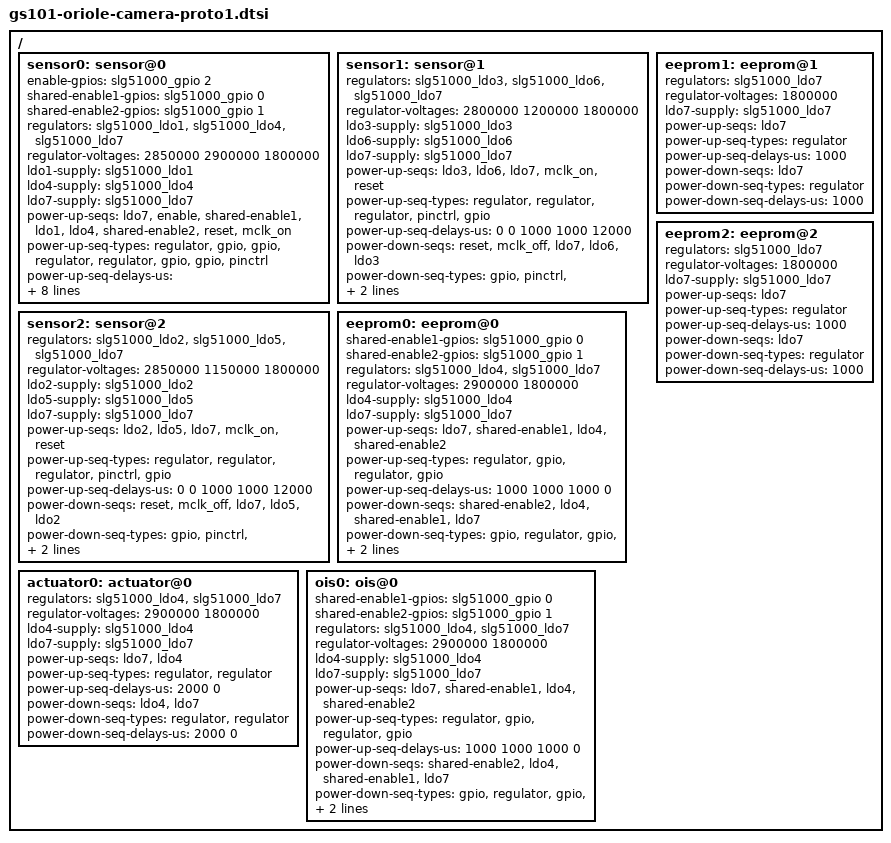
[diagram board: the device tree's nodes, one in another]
// SPDX-License-Identifier: GPL-2.0-only
/*
 * gs101 camera lwis device tree source for oriole
 *
 * Copyright 2020 Google LLC.
 *
 */

/ {
	fragment@lwiscamera {
		target-path = "/";
		__overlay__ {
			/* REAR CAMERA GN1 */
			sensor0: sensor@0 {
				enable-gpios =
					<&slg51000_gpio 2 GPIO_ACTIVE_HIGH>;

				/* GPIOs */
				shared-enable1-gpios =
					<&slg51000_gpio 0 GPIO_ACTIVE_HIGH>;
				shared-enable2-gpios =
					<&slg51000_gpio 1 GPIO_ACTIVE_HIGH>;

				/* Power supplies */
				regulators =
					<&slg51000_ldo1 &slg51000_ldo4
					 &slg51000_ldo7>;
				regulator-voltages =
					<2850000 2900000
					 1800000>;
				ldo1-supply = <&slg51000_ldo1>;
				ldo4-supply = <&slg51000_ldo4>;
				ldo7-supply = <&slg51000_ldo7>;

				/* Power up sequence */
				power-up-seqs =
					"ldo7",
					"enable",
					"shared-enable1",
					"ldo1",
					"ldo4",
					"shared-enable2",
					"reset",
					"mclk_on";
				power-up-seq-types =
					"regulator",
					"gpio",
					"gpio",
					"regulator",
					"regulator",
					"gpio",
					"gpio",
					"pinctrl";
				power-up-seq-delays-us =
					<1000
					 0
					 1000
					 0
					 1000
					 0
					 1000
					 9000>;

				/* Power down sequence */
				power-down-seqs =
					"mclk_off",
					"reset",
					"shared-enable2",
					"ldo4",
					"ldo1",
					"shared-enable1",
					"enable",
					"ldo7";
				power-down-seq-types =
					"pinctrl",
					"gpio",
					"gpio",
					"regulator",
					"regulator",
					"gpio",
					"gpio",
					"regulator";
				power-down-seq-delays-us =
					<1000
					 0
					 1000
					 0
					 1000
					 0
					 1000
					 0>;
			};

			/* FRONT CAMERA IMX355 */
			sensor1: sensor@1 {
				/* Power supplies */
				regulators =
					<&slg51000_ldo3 &slg51000_ldo6
					 &slg51000_ldo7>;
				regulator-voltages =
					<2800000 1200000
					 1800000>;
				ldo3-supply = <&slg51000_ldo3>;
				ldo6-supply = <&slg51000_ldo6>;
				ldo7-supply = <&slg51000_ldo7>;

				/* Power up sequence */
				power-up-seqs =
					"ldo3",
					"ldo6",
					"ldo7",
					"mclk_on",
					"reset";
				power-up-seq-types =
					"regulator",
					"regulator",
					"regulator",
					"pinctrl",
					"gpio";
				power-up-seq-delays-us =
					<0
					 0
					 1000
					 1000
					 12000>;

				/* Power down sequence */
				power-down-seqs =
					"reset",
					"mclk_off",
					"ldo7",
					"ldo6",
					"ldo3";
				power-down-seq-types =
					"gpio",
					"pinctrl",
					"regulator",
					"regulator",
					"regulator";
				power-down-seq-delays-us =
					<0
					 1000
					 0
					 0
					 0>;
			};

			/* REAR ULTRA WIDE CAMERA IMX386 */
			sensor2: sensor@2 {
				/* Power supplies */
				regulators =
					<&slg51000_ldo2 &slg51000_ldo5
					 &slg51000_ldo7>;
				regulator-voltages =
					<2850000 1150000
					 1800000>;
				ldo2-supply = <&slg51000_ldo2>;
				ldo5-supply = <&slg51000_ldo5>;
				ldo7-supply = <&slg51000_ldo7>;

				/* Power up sequence */
				power-up-seqs =
					"ldo2",
					"ldo5",
					"ldo7",
					"mclk_on",
					"reset";
				power-up-seq-types =
					"regulator",
					"regulator",
					"regulator",
					"pinctrl",
					"gpio";
				power-up-seq-delays-us =
					<0
					 0
					 1000
					 1000
					 12000>;

				/* Power down sequence */
				power-down-seqs =
					"reset",
					"mclk_off",
					"ldo7",
					"ldo5",
					"ldo2";
				power-down-seq-types =
					"gpio",
					"pinctrl",
					"regulator",
					"regulator",
					"regulator";
				power-down-seq-delays-us =
					<0
					 1000
					 0
					 0
					 0>;
			};

			/* Eeprom lc898128 for gn1*/
			eeprom0: eeprom@0 {
				/* GPIOs */
				shared-enable1-gpios =
					<&slg51000_gpio 0 GPIO_ACTIVE_HIGH>;
				shared-enable2-gpios =
					<&slg51000_gpio 1 GPIO_ACTIVE_HIGH>;

				/* Power supplies */
				regulators = <&slg51000_ldo4 &slg51000_ldo7>;
				regulator-voltages = <2900000 1800000>;
				ldo4-supply = <&slg51000_ldo4>;
				ldo7-supply = <&slg51000_ldo7>;

				/* Power up sequence */
				power-up-seqs =
					"ldo7",
					"shared-enable1",
					"ldo4",
					"shared-enable2";
				power-up-seq-types =
					"regulator",
					"gpio",
					"regulator",
					"gpio";
				power-up-seq-delays-us =
					<1000
					 1000
					 1000
					 0>;

				/* Power down sequence */
				power-down-seqs =
					"shared-enable2",
					"ldo4",
					"shared-enable1",
					"ldo7";
				power-down-seq-types =
					"gpio",
					"regulator",
					"gpio",
					"regulator";
				power-down-seq-delays-us =
					<1000
					 1000
					 1000
					 0>;
			};

			/* Eeprom m24c64s for imx355 */
			eeprom1: eeprom@1 {
				/* Power supplies */
				regulators = <&slg51000_ldo7>;
				regulator-voltages = <1800000>;
				ldo7-supply = <&slg51000_ldo7>;

				/* Power up sequence */
				power-up-seqs =
					"ldo7";
				power-up-seq-types =
					"regulator";
				power-up-seq-delays-us =
					<1000>;

				/* Power down sequence */
				power-down-seqs =
					"ldo7";
				power-down-seq-types =
					"regulator";
				power-down-seq-delays-us =
					<1000>;
			};

			/* Eeprom m24c64x for imx386 */
			eeprom2: eeprom@2 {
				/* Power supplies */
				regulators = <&slg51000_ldo7>;
				regulator-voltages = <1800000>;
				ldo7-supply = <&slg51000_ldo7>;

				/* Power up sequence */
				power-up-seqs =
					"ldo7";
				power-up-seq-types =
					"regulator";
				power-up-seq-delays-us =
					<1000>;

				/* Power down sequence */
				power-down-seqs =
					"ldo7";
				power-down-seq-types =
					"regulator";
				power-down-seq-delays-us =
					<1000>;
			};

			/* Actuator ak7377 for gn1*/
			actuator0: actuator@0 {
				/* Power supplies */
				regulators = <&slg51000_ldo4 &slg51000_ldo7>;
				regulator-voltages = <2900000 1800000>;
				ldo4-supply = <&slg51000_ldo4>;
				ldo7-supply = <&slg51000_ldo7>;

				/* Power up sequence */
				power-up-seqs =
					"ldo7",
					"ldo4";
				power-up-seq-types =
					"regulator",
					"regulator";
				power-up-seq-delays-us =
					<2000
					 0>;

				/* Power down sequence */
				power-down-seqs =
					"ldo4",
					"ldo7";
				power-down-seq-types =
					"regulator",
					"regulator";
				power-down-seq-delays-us =
					<2000
					 0>;
			};

			/* Ois lc898128 for gn1*/
			ois0: ois@0 {
				/* GPIOs */
				shared-enable1-gpios =
					<&slg51000_gpio 0 GPIO_ACTIVE_HIGH>;
				shared-enable2-gpios =
					<&slg51000_gpio 1 GPIO_ACTIVE_HIGH>;

				/* Power supplies */
				regulators = <&slg51000_ldo4 &slg51000_ldo7>;
				regulator-voltages = <2900000 1800000>;
				ldo4-supply = <&slg51000_ldo4>;
				ldo7-supply = <&slg51000_ldo7>;

				/* Power up sequence */
				power-up-seqs =
					"ldo7",
					"shared-enable1",
					"ldo4",
					"shared-enable2";
				power-up-seq-types =
					"regulator",
					"gpio",
					"regulator",
					"gpio";
				power-up-seq-delays-us =
					<1000
					 1000
					 1000
					 0>;

				/* Power down sequence */
				power-down-seqs =
					"shared-enable2",
					"ldo4",
					"shared-enable1",
					"ldo7";
				power-down-seq-types =
					"gpio",
					"regulator",
					"gpio",
					"regulator";
				power-down-seq-delays-us =
					<1000
					 1000
					 1000
					 0>;
			};
		};
	};
};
